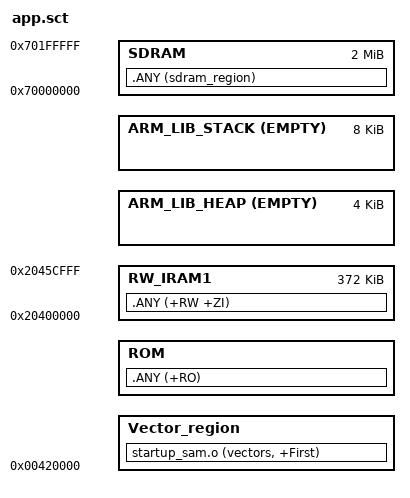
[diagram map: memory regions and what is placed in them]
; * ----------------------------------------------------------------------------
; *         ATMEL Microcontroller Software Support
; * ----------------------------------------------------------------------------
; * Copyright (c) 2009, Atmel Corporation
; *
; * All rights reserved.
; *
; * Redistribution and use in source and binary forms, with or without
; * modification, are permitted provided that the following conditions are met:
; *
; * - Redistributions of source code must retain the above copyright notice,
; * this list of conditions and the disclaimer below.
; *
; * Atmel's name may not be used to endorse or promote products derived from
; * this software without specific prior written permission.
; *
; * DISCLAIMER: THIS SOFTWARE IS PROVIDED BY ATMEL "AS IS" AND ANY EXPRESS OR
; * IMPLIED WARRANTIES, INCLUDING, BUT NOT LIMITED TO, THE IMPLIED WARRANTIES OF
; * MERCHANTABILITY, FITNESS FOR A PARTICULAR PURPOSE AND NON-INFRINGEMENT ARE
; * DISCLAIMED. IN NO EVENT SHALL ATMEL BE LIABLE FOR ANY DIRECT, INDIRECT,
; * INCIDENTAL, SPECIAL, EXEMPLARY, OR CONSEQUENTIAL DAMAGES (INCLUDING, BUT NOT
; * LIMITED TO, PROCUREMENT OF SUBSTITUTE GOODS OR SERVICES; LOSS OF USE, DATA,
; * OR PROFITS; OR BUSINESS INTERRUPTION) HOWEVER CAUSED AND ON ANY THEORY OF
; * LIABILITY, WHETHER IN CONTRACT, STRICT LIABILITY, OR TORT (INCLUDING
; * NEGLIGENCE OR OTHERWISE) ARISING IN ANY WAY OUT OF THE USE OF THIS SOFTWARE,
; * EVEN IF ADVISED OF THE POSSIBILITY OF SUCH DAMAGE.
; * ----------------------------------------------------------------------------

; *------------------------------------------------------------------------------
; *      Linker scatter for running in internal FLASH on the SAMV71
; *----------------------------------------------------------------------------*/

; /* vector is put at very begin address of FLASH, the preserved size is 0x100 */

LR_IROM1 0x00420000 0x001E0000  ; load region size_region
{
    Vector_region 0x00420000 +0; load address = execution address;
    {
        startup_sam.o (vectors, +First)
    }

    ROM +0
    {
        .ANY (+RO)
    }

    RW_IRAM1 0x20400000 0x0005D000 ; RW data
    {
        .ANY (+RW +ZI)
    }

 
   ; Configure Stack and Heap
    ARM_LIB_HEAP +0 ALIGN 8 EMPTY 0x1000
    {
    }

    ARM_LIB_STACK +0 EMPTY 0x2000
    {
    }

    
    ; Configure SDRAM region
    SDRAM 0x70000000 0x200000 
    {
        .ANY (sdram_region) 
    }
}

